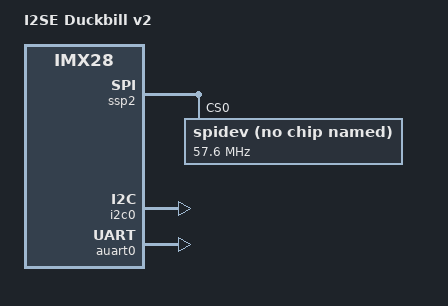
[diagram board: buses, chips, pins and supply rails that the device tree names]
/*
 * Copyright (C) 2015 I2SE GmbH <info@i2se.com>
 *
 * The code contained herein is licensed under the GNU General Public
 * License. You may obtain a copy of the GNU General Public License
 * Version 2 or later at the following locations:
 *
 * http://www.opensource.org/licenses/gpl-license.html
 * http://www.gnu.org/copyleft/gpl.html
 */

/dts-v1/;
#include "imx28-duckbill-v2.dtsi"

/ {
	model = "I2SE Duckbill v2";
	compatible = "i2se,duckbill", "fsl,imx28";

	apb@80000000 {
		apbh@80000000 {
			ssp2: ssp@80014000 {
				compatible = "fsl,imx28-spi";
				pinctrl-names = "default";
				pinctrl-0 = <&spi2_pins_a>;
				status = "okay";

				spidev: spidev@0 {
					compatible = "spidev";
					reg = <0>;
					spi-max-frequency = <57600000>;
				};
			};
		};

		apbx@80040000 {
			i2c0: i2c@80058000 {
				pinctrl-names = "default";
				pinctrl-0 = <&i2c0_pins_a>;
				status = "okay";
			};

			auart0: serial@8006a000 {
				pinctrl-names = "default";
				pinctrl-0 = <&auart0_2pins_a>;
				status = "okay";
			};
		};
	};
};
